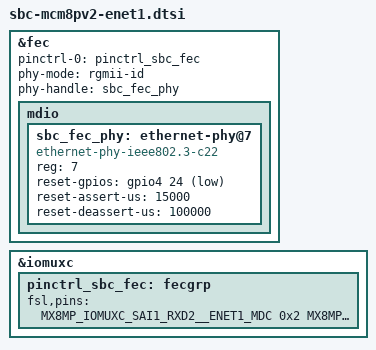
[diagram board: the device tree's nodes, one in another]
// SPDX-License-Identifier: (GPL-2.0+ OR MIT)
/* Copyright 2026 CompuLab Ltd. */

&fec {
	pinctrl-names = "default";
	pinctrl-0 = <&pinctrl_sbc_fec>;
	phy-mode = "rgmii-id";
	phy-handle = <&sbc_fec_phy>;
	status = "okay";

	mdio {
		#address-cells = <1>;
		#size-cells = <0>;

		/*
		 * Address 7 confirmed on hardware; schematic annotation says 5.
		 * TBD: to talk to the HW engineer.
		 */
		sbc_fec_phy: ethernet-phy@7 {
			compatible = "ethernet-phy-ieee802.3-c22";
			reg = <7>;
			reset-gpios = <&gpio4 24 GPIO_ACTIVE_LOW>;
			reset-assert-us = <15000>;
			reset-deassert-us = <100000>;
		};
	};
};

&iomuxc {
	pinctrl_sbc_fec: fecgrp {
		fsl,pins = <
			MX8MP_IOMUXC_SAI1_RXD2__ENET1_MDC		0x2
			MX8MP_IOMUXC_SAI1_RXD3__ENET1_MDIO		0x2
			MX8MP_IOMUXC_SAI1_RXD4__ENET1_RGMII_RD0		0x90
			MX8MP_IOMUXC_SAI1_RXD5__ENET1_RGMII_RD1		0x90
			MX8MP_IOMUXC_SAI1_RXD6__ENET1_RGMII_RD2		0x90
			MX8MP_IOMUXC_SAI1_RXD7__ENET1_RGMII_RD3		0x90
			MX8MP_IOMUXC_SAI1_TXC__ENET1_RGMII_RXC		0x90
			MX8MP_IOMUXC_SAI1_TXFS__ENET1_RGMII_RX_CTL	0x90
			MX8MP_IOMUXC_SAI1_TXD0__ENET1_RGMII_TD0		0x16
			MX8MP_IOMUXC_SAI1_TXD1__ENET1_RGMII_TD1		0x16
			MX8MP_IOMUXC_SAI1_TXD2__ENET1_RGMII_TD2		0x16
			MX8MP_IOMUXC_SAI1_TXD3__ENET1_RGMII_TD3		0x16
			MX8MP_IOMUXC_SAI1_TXD4__ENET1_RGMII_TX_CTL	0x16
			MX8MP_IOMUXC_SAI1_TXD5__ENET1_RGMII_TXC		0x16
			MX8MP_IOMUXC_SAI2_TXFS__GPIO4_IO24		0x10
		>;
	};
};
